AUTOSAR XML (schema 4-2-2)
package /Components
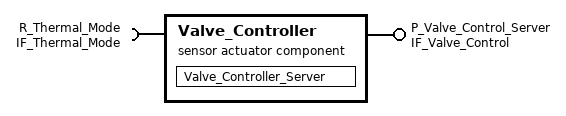
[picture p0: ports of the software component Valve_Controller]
  sensor actuator sw component type Valve_Controller
    provide port P_Valve_Control_Server: provided-interface=IF_Valve_Control
    require port R_Thermal_Mode: required-interface=IF_Thermal_Mode
    behavior Valve_Controller_InternalBehavior
      init event Valve_Controller_Init_Event: start-on-event=Valve_Controller_Server
      operation invoked event Valve_Command_Invoked: start-on-event=Valve_Controller_Server
      runnable Valve_Controller_Server: mode-access-point=R_Thermal_Mode.ThermalModeGroup
        data-receive-point-by-arguments:
          access VA_Arg_valve_position: accessed-variable=P_Valve_Control_Server.target_motor_coolant_flow
          access VA_Arg_status_query: accessed-variable=P_Valve_Control_Server.motor_cooling_status
